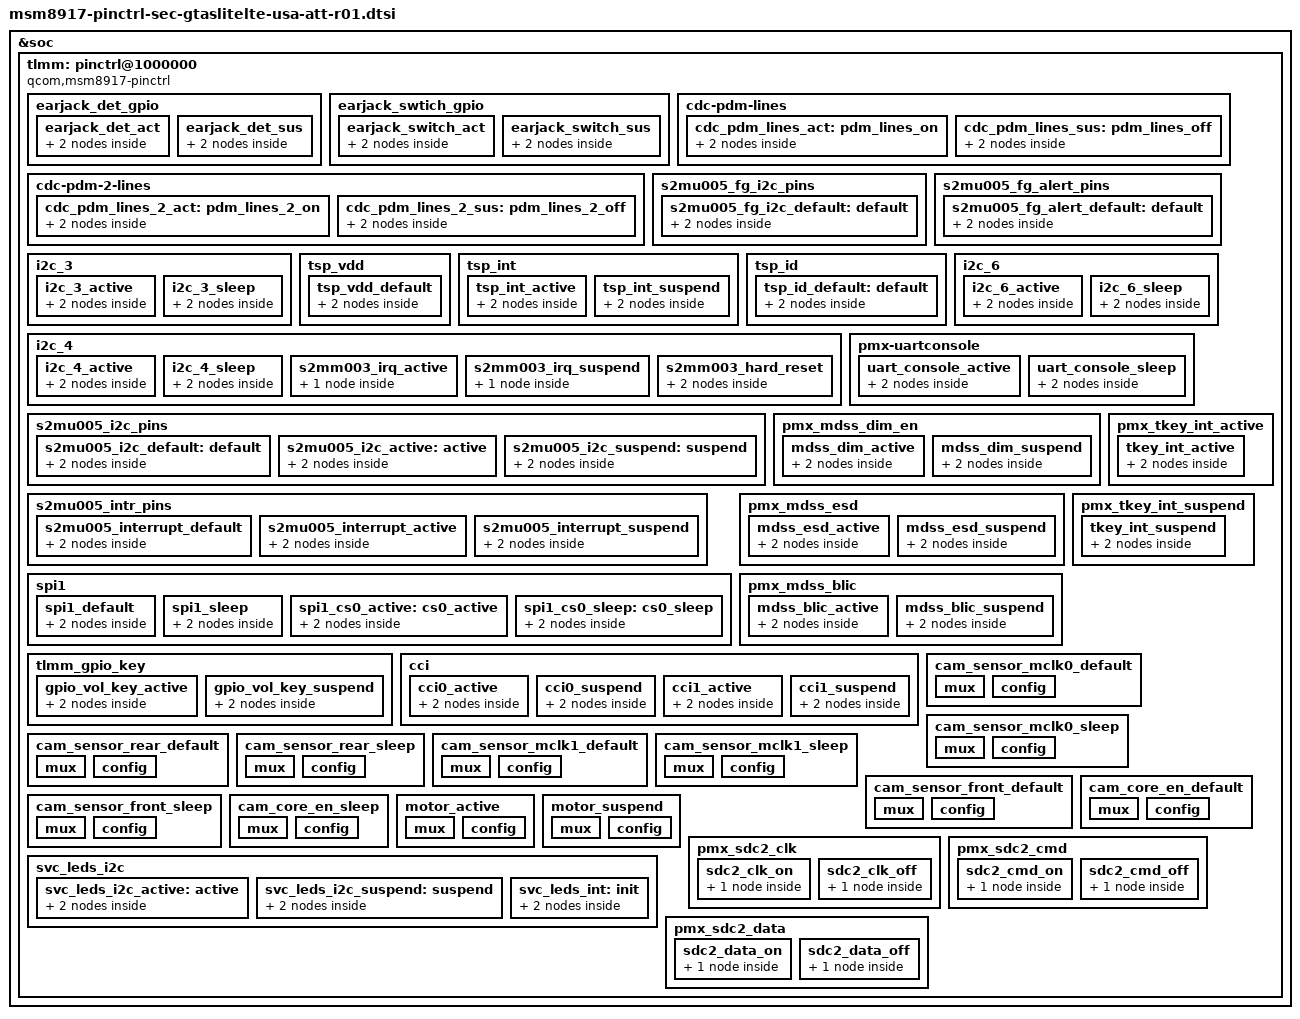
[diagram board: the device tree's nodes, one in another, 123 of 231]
/*
 * Copyright (c) 2015, The Linux Foundation. All rights reserved.
 *
 * This program is free software; you can redistribute it and/or modify
 * it under the terms of the GNU General Public License version 2 and
 * only version 2 as published by the Free Software Foundation.
 *
 * This program is distributed in the hope that it will be useful,
 * but WITHOUT ANY WARRANTY; without even the implied warranty of
 * MERCHANTABILITY or FITNESS FOR A PARTICULAR PURPOSE.  See the
 * GNU General Public License for more details.
 */

/*#include "../../qcom/msm8917-pinctrl.dtsi"*/

&soc {
	tlmm: pinctrl@1000000 {
		compatible = "qcom,msm8917-pinctrl";
		reg = <0x1000000 0x300000>;
		interrupts = <0 208 0>;
		gpio-controller;
		#gpio-cells = <2>;
		interrupt-controller;
		#interrupt-cells = <2>;

		earjack_det_gpio {
				earjack_det_act: earjack_det_act {
					mux {
						pins = "gpio61";
						function = "gpio";
					};

					config {
						pins = "gpio61";
						drive-strength = <2>;
						bias-disable;
					};
				};
				earjack_det_sus: earjack_det_sus {
					mux {
						pins = "gpio61";
						function = "gpio";
					};

					config {
						pins = "gpio61";
						drive-strength = <2>;
						bias-disable;
					};
				};
		};

		earjack_swtich_gpio {
				earjack_switch_act: earjack_switch_act {
					mux {
						pins = "gpio93";
						function = "gpio";
					};

					config {
						pins = "gpio93";
						drive-strength = <2>;
						bias-disable;
					};
				};
				earjack_switch_sus: earjack_switch_sus {
					mux {
						pins = "gpio93";
						function = "gpio";
					};

					config {
						pins = "gpio93";
						drive-strength = <2>;
						bias-disable;
					};
				};
		};

		cdc-pdm-2-lines {
			cdc_pdm_lines_2_act: pdm_lines_2_on {
				mux {
					pins = "gpio70", "gpio71", "gpio72";
					function = "cdc_pdm0";
				};

				config {
					pins = "gpio70", "gpio71", "gpio72";
					drive-strength = <2>;
					bias-pull-down;
				};
			};

			cdc_pdm_lines_2_sus: pdm_lines_2_off {
				mux {
					pins = "gpio70", "gpio71", "gpio72";
					function = "cdc_pdm0";
				};

				config {
					pins = "gpio70", "gpio71", "gpio72";
					drive-strength = <2>;
					bias-pull-down;
				};
			};
		};

		cdc-pdm-lines {
			cdc_pdm_lines_act: pdm_lines_on {
				mux {
					pins = "gpio69", "gpio73", "gpio74";
					function = "cdc_pdm0";
				};

				config {
					pins = "gpio69", "gpio73", "gpio74";
					drive-strength = <2>;
					bias-pull-down;
				};
			};
			cdc_pdm_lines_sus: pdm_lines_off {
				mux {
					pins = "gpio69", "gpio73", "gpio74";
					function = "cdc_pdm0";
				};

				config {
					pins = "gpio69", "gpio73", "gpio74";
					drive-strength = <2>;
					bias-pull-down;
				};
			};
		};

		/* Fuelgauge I2C pins */
		s2mu005_fg_i2c_pins {

			s2mu005_fg_i2c_default: default {
				/* default state */
				mux {
					pins = "gpio6", "gpio7";
					function = "gpio";
				};

				config {
					pins = "gpio6", "gpio7";
					drive-strength = <2>;
					bias-disable;
				};
			};

		};

		/* Fuelgauge alert pin */
                s2mu005_fg_alert_pins {

                        s2mu005_fg_alert_default: default {
                                /* default state */
                                mux {
                                        pins = "gpio63";
                                        function = "gpio";
                                };

                                config {
                                        pins = "gpio63";
                                        drive-strength = <2>;
                                        bias-disable;
                                };
                        };

                };

		/* pingrp for tsp - start */
		i2c_3 {
			i2c_3_active: i2c_3_active {
				/* active state */
				mux {
					pins = "gpio10", "gpio11";
					function = "blsp_i2c3";
				};

				config {
					pins = "gpio10", "gpio11";
					drive-strength = <2>;
					bias-disable;
				};
			};

			i2c_3_sleep: i2c_3_sleep {
				/* suspended state */
				mux {
					pins = "gpio10", "gpio11";
					function = "blsp_i2c3";
				};

				config {
					pins = "gpio10", "gpio11";
					drive-strength = <2>;
					bias-disable;
				};
			};
		};

		tsp_vdd {
			tsp_vdd_default: tsp_vdd_default {
				/* default state */
				mux {
					pins = "gpio92";
					function = "gpio";
				};
				config {
					pins = "gpio92";
					drive-strength = <2>;
					bias-disable;
				};
			};
		};

		tsp_int {
			tsp_int_active: tsp_int_active {
				mux {
					pins = "gpio65";
					function = "gpio";
				};

				config {
					pins = "gpio65";
					drive-strength = <2>;
					bias-disable;
				};
			};

			tsp_int_suspend: tsp_int_suspend {
				mux {
					pins = "gpio65";
					function = "gpio";
				};

				config {
					pins = "gpio65";
					drive-strength = <2>;
					bias-pull-down;
				};
			};
		};

		tsp_id {
			tsp_id_default: default {
				mux {
					pins = "gpio24";
					function = "gpio";
				};

				config {
					pins = "gpio24";
					drive-strength = <2>;
					bias-disable;
				};
			};
		};

		i2c_6 {
			i2c_6_active: i2c_6_active {
				/* active state */
				mux {
					pins = "gpio22", "gpio23";
					function = "blsp_i2c6";
				};

				config {
					pins = "gpio22", "gpio23";
					drive-strength = <2>;
					bias-disable;
				};
			};

			i2c_6_sleep: i2c_6_sleep {
				/* suspended state */
				mux {
					pins = "gpio22", "gpio23";
					function = "blsp_i2c6";
				};

				config {
					pins = "gpio22", "gpio23";
					drive-strength = <2>;
					bias-disable;
				};
			};
		};

		i2c_4 {
			i2c_4_active: i2c_4_active {
				/* active state */
				mux {
					pins = "gpio14", "gpio15";
					function = "NA";
				};

				config {
					pins = "gpio14", "gpio15";
					drive-strength = <2>;
					bias-pull-down;
					input-low;
				};
			};

			i2c_4_sleep: i2c_4_sleep {
				/* suspended state */
				mux {
					pins = "gpio14", "gpio15";
					function = "NA";
				};

				config {
					pins = "gpio14", "gpio15";
					drive-strength = <2>;
					bias-pull-down;
					input-low;
				};
			};

			s2mm003_irq_active: s2mm003_irq_active {
				i2c_4 {
					pins = "gpio48";
					drive-strength = <2>;
					function = "NA";
					bias-pull-down;
					input-low;
				};
			};

			s2mm003_irq_suspend: s2mm003_irq_suspend {
				i2c_4 {
					pins = "gpio48";
			    	drive-strength = <2>;
					function = "NA";
					bias-pull-down;
					input-low;
				};
			};

			s2mm003_hard_reset: s2mm003_hard_reset {
				mux {
					pins = "gpio14", "gpio15";
					function = "gpio";
				};

				config { 
					pins = "gpio14", "gpio15";
					drive-strength = <6>; 
					bias-pull-down;
					output-low;
				}; 
			};
		};

		/* MUIC - S2MU005 */
		s2mu005_i2c_pins {
			s2mu005_i2c_default: default {
				/* default state*/
				mux {
					pins = "gpio18", "gpio19"; /* SDA, SCL */
                        		function = "gpio";
				};
				config {
					pins = "gpio18", "gpio19";
					drive-strength = <2>;
					bias-disable;
				};
			};
	
			s2mu005_i2c_active: active {
				/*active state*/
				 mux {
                                        pins = "gpio18", "gpio19"; /* SDA, SCL */
                                        function = "gpio";
                                };
                                config {
                                        pins = "gpio18", "gpio19";
                                        drive-strength = <2>;
                                        bias-disable;
                                };
		
			};
			s2mu005_i2c_suspend: suspend {
				/*suspend state*/
				 mux {
                                        pins = "gpio18", "gpio19"; /* SDA, SCL */
                                        function = "gpio";
                                };
                                config {
                                        pins = "gpio18", "gpio19";
                                        drive-strength = <2>;
                                        bias-disable;
                                };

			};
		};

		s2mu005_intr_pins {
			s2mu005_interrupt_default: s2mu005_interrupt_default {
				/*default state*/
				mux {
					pins = "gpio35";
					function = "gpio";
				};
				config {
					pins = "gpio35";
					drive-strength = <2>;
					bias-disable;
				};
			};

			s2mu005_interrupt_active: s2mu005_interrupt_active {
				/*active state*/
				mux {
                                        pins = "gpio35";
                                        function = "gpio";
                                };
                                config {
                                        pins = "gpio35";
                                        drive-strength = <2>;
                                        bias-disable;
                                };
		
			};
			s2mu005_interrupt_suspend: s2mu005_interrupt_suspend {
				/*suspend state*/
				 mux {
                                        pins = "gpio35";
                                        function = "gpio";
                                };
                                config {
                                        pins = "gpio35";
                                        drive-strength = <2>;
                                        bias-disable;
                                };
			};
		};

		spi1 {
			spi1_default: spi1_default {
				/* active state */
				mux {
					/* MOSI, MISO, CLK */
					pins = "gpio0", "gpio1", "gpio3";
					function = "blsp_spi1";
				};

				config {
					pins = "gpio0", "gpio1", "gpio3";
					drive-strength = <2>; /* 12 MA */
					bias-disable = <0>; /* No PULL */
					input-low;
				};
			};

			spi1_sleep: spi1_sleep {
				/* suspended state */
				mux {
					/* MOSI, MISO, CLK */
					pins = "gpio0", "gpio1", "gpio3";
					function = "gpio";
				};

				config {
					pins = "gpio0", "gpio1", "gpio3";
					drive-strength = <2>; /* 2 MA */
					bias-pull-down; /* PULL Down */
					input-low;
				};
			};

			spi1_cs0_active: cs0_active {
				/* CS */
				mux {
					pins = "gpio2";
					function = "blsp_spi1";
				};

				config {
					pins = "gpio2";
					drive-strength = <2>;
					bias-disable = <0>;
				};
			};

			spi1_cs0_sleep: cs0_sleep {
				/* CS */
				mux {
					pins = "gpio2";
					function = "gpio";
				};

				config {
					pins = "gpio2";
					drive-strength = <2>;
					bias-disable = <0>;
				};
			};
		};

		pmx-uartconsole {
			uart_console_active: uart_console_active {
				mux {
					pins = "gpio4", "gpio5";
					function = "blsp_uart2";
				};

				config {
					pins = "gpio4", "gpio5";
					drive-strength = <2>;
					bias-pull-up;
				};
			};

			uart_console_sleep: uart_console_sleep {
				mux {
					pins = "gpio4", "gpio5";
					function = "blsp_uart2";
				};

				config {
					pins = "gpio4", "gpio5";
					drive-strength = <2>;
					bias-pull-down;
				};
			};
		};

		pmx_mdss_dim_en: pmx_mdss_dim_en {
			mdss_dim_active: mdss_dim_active {
				mux {
					pins = "gpio45";
					function = "gpio";
				};

				config {
					pins = "gpio45";
					drive-strength = <8>; /* 8 mA */
					bias-pull-down; /* pull down*/
					input-low;
				};
			};
			mdss_dim_suspend: mdss_dim_suspend {
				mux {
					pins = "gpio45";
				};

				config {
					pins = "gpio45";

					drive-strength = <2>; /* 2 mA */
					bias-disable; /* NO pull */
					output-low;
				};
			};
		};
		pmx_mdss_esd: pmx_mdss_esd {
			mdss_esd_active: mdss_esd_active {
				mux {
					pins = "gpio90";
					function = "gpio";
				};

				config {
					pins = "gpio90";
					drive-strength = <8>; /* 8 mA */
					bias-disable; /* NO pull */
					input-enable;
				};
			};
		mdss_esd_suspend: mdss_esd_suspend {
				mux {
					pins = "gpio90";
				};

				config {
					pins = "gpio90";

					drive-strength = <2>; /* 2 mA */
					bias-pull-down; /* pull down*/
					input-enable;
				};
			};
		};

		pmx_mdss_blic: pmx_mdss_blic {
			/* ON_CELL BLIC control */
			mdss_blic_active: mdss_blic_active {
				mux {
					pins = "gpio87", "gpio8"; /* BLIC */
					function = "gpio";
				};

				config {
					pins = "gpio87", "gpio8"; /* BLIC */
					drive-strength = <8>; /* 8 mA */
					bias-disable; /* No PULL */
					output-high;
				};
			};
			mdss_blic_suspend: mdss_blic_suspend {
				mux {
					pins = "gpio87", "gpio8"; /* BLIC */
					function = "gpio";
				};

				config {
					pins = "gpio87", "gpio8"; /* BLIC */
					drive-strength = <2>; /* 2 mA */
					bias-disable; /* No PULL */
					output-low;
				};
			};
		};

		pmx_tkey_int_active {
			tkey_int_active: tkey_int_active {
				mux {
					pins = "gpio48";
					function = "gpio";
				};

				config {
					pins = "gpio48";
					drive-strength = <8>;
					bias-disable;
				};
			};
		};

		pmx_tkey_int_suspend {
			tkey_int_suspend: tkey_int_suspend {
				mux {
					pins = "gpio48";
					function = "gpio";
				};

				config {
					pins = "gpio48";
					drive-strength = <2>;
					bias-pull-down;
				};
			};
		};
/*
		pmx_tkey_i2c_active {
			tkey_i2c_active: tkey_i2c_active {
				mux {
					pins = "gpio88";
					function = "gpio";
				};

				config {
					pins = "gpio88";
					drive-strength = <8>;
					bias-disable;
				};
			};
		};

		pmx_tkey_i2c_suspend {
			tkey_i2c_suspend: tkey_i2c_suspend {
				mux {
					pins = "gpio88";
					function = "gpio";
				};

				config {
					pins = "gpio88";
					drive-strength = <2>;
					bias-pull-down;
				};
			};
		};
*/
		tlmm_gpio_key {
			gpio_vol_key_active: gpio_vol_key_active {
				mux {
					pins = "gpio127";
					function = "gpio";
				};

				config {
					pins = "gpio127";
					drive-strength = <2>;
					bias-pull-up; /* pull up */
				};
			};

			gpio_vol_key_suspend: gpio_vol_key_suspend {
				mux {
					pins = "gpio127";
					function = "gpio";
				};

				config {
					pins = "gpio127";
					drive-strength = <2>;
					bias-pull-up; /* pull up */
				};
			};
		};

		cci {
			cci0_active: cci0_active {
				/* cci0 active state */
				mux {
					/* CLK, DATA */
					pins = "gpio29", "gpio30";
					function = "cci_i2c";
				};

				config {
					pins = "gpio29", "gpio30";
					drive-strength = <2>; /* 2 MA */
					bias-disable; /* No PULL */
				};
			};

			cci0_suspend: cci0_suspend {
				/* cci0 suspended state */
				mux {
					/* CLK, DATA */
					pins = "gpio29", "gpio30";
					function = "gpio";
				};

				config {
					pins = "gpio29", "gpio30";
					drive-strength = <2>; /* 2 MA */
					bias-disable; /* No PULL */
				};
			};

			cci1_active: cci1_active {
				/* cci1 active state */
				mux {
					/* CLK, DATA */
					pins = "gpio31", "gpio32";
					function = "cci_i2c";
				};

				config {
					pins = "gpio31", "gpio32";
					drive-strength = <2>; /* 2 MA */
					bias-pull-down; /*PULL-DOWN*/
				};
			};

			cci1_suspend: cci1_suspend {
				/* cci1 suspended state */
				mux {
					/* CLK, DATA */
					pins = "gpio31", "gpio32";
					function = "gpio";
				};

				config {
					pins = "gpio31", "gpio32";
					drive-strength = <2>; /* 2 MA */
					bias-pull-down; /*PULL-DOWN*/
				};
			};
		};

		/*sensors */
		cam_sensor_mclk0_default: cam_sensor_mclk0_default {
			/* MCLK0 */
			mux {
				/* CLK, DATA */
				pins = "gpio26";
				function = "cam_mclk";
			};

			config {
				pins = "gpio26";
				bias-disable; /* No PULL */
				drive-strength = <4>; /* 4 MA */
				output-low;
			};
		};

		cam_sensor_mclk0_sleep: cam_sensor_mclk0_sleep {
			/* MCLK0 */
			mux {
				/* CLK, DATA */
				pins = "gpio26";
				function = "cam_mclk";
			};

			config {
				pins = "gpio26";
				bias-pull-down; /* PULL-DOWN */
				drive-strength = <4>; /* 4 MA */
				output-low;
			};
		};

		cam_sensor_rear_default: cam_sensor_rear_default {
			/* RESET, STANDBY */
			mux {
				pins = "gpio36", "gpio41";
				function = "gpio";
			};

			config {
				pins = "gpio36", "gpio41";
				bias-pull-down; /* PULL DOWN */
				drive-strength = <2>; /* 2 MA */
				output-low;
			};
		};

		cam_sensor_rear_sleep: cam_sensor_rear_sleep {
			/* RESET, STANDBY */
			mux {
				pins = "gpio36", "gpio41";
				function = "gpio";
			};

			config {
				pins = "gpio36", "gpio41";
				bias-pull-down; /* NO PULL */
				drive-strength = <2>; /* 2 MA */
				output-low;
			};
		};

		cam_sensor_mclk1_default: cam_sensor_mclk1_default {
			/* MCLK1 */
			mux {
				/* CLK, DATA */
				pins = "gpio27";
				function = "cam_mclk";
			};

			config {
				pins = "gpio27";
				bias-disable; /* No PULL */
				drive-strength = <4>; /* 2 MA */
				output-low;
			};
		};

		cam_sensor_mclk1_sleep: cam_sensor_mclk1_sleep {
			/* MCLK1 */
			mux {
				/* CLK, DATA */
				pins = "gpio27";
				function = "cam_mclk";
			};

			config {
				pins = "gpio27";
				bias-pull-down; /* PULL DOWN */
				drive-strength = <4>; /* 2 MA */
				output-low;
			};
		};

		cam_sensor_front_default: cam_sensor_front_default {
			/* RESET, STANDBY */
			mux {
				pins = "gpio38","gpio40";
				function = "gpio";
			};

			config {
				pins = "gpio38","gpio40";
				bias-pull-down; /* PULL DOWN */
				drive-strength = <2>; /* 2 MA */
				output-low;
			};
		};

		cam_sensor_front_sleep: cam_sensor_front_sleep {
			/* RESET, STANDBY */
			mux {
				pins = "gpio38","gpio40";
				function = "gpio";
			};

			config {
				pins = "gpio38","gpio40";
				bias-pull-down; /* NO PULL */
				drive-strength = <2>; /* 2 MA */
				output-low;
			};
		};





		cam_core_en_default: cam_core_en_default {
			mux {
				pins =  "gpio39","gpio88";
				function = "gpio";
			};

			config {
				pins ="gpio39","gpio88";
				bias-pull-down; /* PULL DOWN */
				drive-strength = <2>;
				output-low;
			};
		};

		cam_core_en_sleep: cam_core_en_sleep {
			mux {
				pins = "gpio39","gpio88";
				function = "gpio";
			};

			config {
				pins = "gpio39","gpio88";
				bias-pull-down; /* NO PULL */
				drive-strength = <2>;
				output-low;
			};
		};




		/* add pinctrl for motor  */
		motor_active: motor_active {
			mux {
				pins = "gpio40";
				function = "gpio";
			};

			config {
				pins = "gpio40";
				bias-disable;
				drive-strength = <2>;
				/*output-high;*/
			};
		};

		motor_suspend: motor_suspend {
			mux {
				pins = "gpio40";
				function = "gpio";
			};

			config {
				pins = "gpio40";
				bias-disable;
				drive-strength = <2>;
				/*output-low;*/
			};
		};

		svc_leds_i2c {
			svc_leds_i2c_active: active {
				mux {
					pins = "gpio12" , "gpio13"; /* SDA, SCL */
					function = "NA";
				};

				config {
					pins = "gpio12", "gpio13";
					bias-disable;
					drive-strength = <2>;
				};
			};

			svc_leds_i2c_suspend: suspend {
				mux {
					pins = "gpio12" , "gpio13"; /* SDA, SCL */
					function = "NA";
				};

				config {
					pins = "gpio12", "gpio13";
					bias-disable;
					drive-strength = <2>;
				};
			};

			svc_leds_int: init {
				mux {
					pins = "gpio8";
					function = "gpio";
				};

				config {
					pins = "gpio8";
					bias-disable;
					drive-strength = <2>;
					output-high;
				};
        		};
		};

                pmx_sdc2_clk {
                        sdc2_clk_on: sdc2_clk_on {
                                config {
                                        pins = "sdc2_clk";
                                        drive-strength = <16>; /* 16 MA */
                                        bias-disable; /* NO pull */
                                };
                        };

                        sdc2_clk_off: sdc2_clk_off {
                                config {
                                        pins = "sdc2_clk";
                                        bias-disable; /* NO pull */
                                        drive-strength = <2>; /* 2 MA */
                                };
                        };
                };

                pmx_sdc2_cmd {
                        sdc2_cmd_on: sdc2_cmd_on {
                                config {
                                        pins = "sdc2_cmd";
                                        bias-pull-up; /* pull up */
                                        drive-strength = <8>; /* 8 MA */
                                };
                        };

                        sdc2_cmd_off: sdc2_cmd_off {
                                config {
                                        pins = "sdc2_cmd";
                                        bias-pull-up; /* pull up */
                                        drive-strength = <2>; /* 2 MA */
                                };
                        };
                };

                pmx_sdc2_data {
                        sdc2_data_on: sdc2_data_on {
                                config {
                                        pins = "sdc2_data";
                                        bias-pull-up; /* pull up */
                                        drive-strength = <8>; /* 8 MA */
                                };
                        };

                        sdc2_data_off: sdc2_data_off {
                                config {
                                        pins = "sdc2_data";
                                        bias-pull-up; /* pull up */
                                        drive-strength = <2>; /* 2 MA */
                                };
                         };
                };
	};
};
